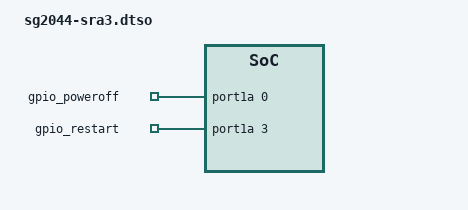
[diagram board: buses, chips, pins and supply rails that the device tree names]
/dts-v1/;
/plugin/;

&port1a {

	gpio_poweroff: gpio-poweroff {
		compatible = "gpio-poweroff";
		gpios = <&port1a 0 0>;
		active-delay-ms = <300>;
		inactive-delay-ms = <300>;
	};

	gpio_restart: gpio-restart {
		compatible = "gpio-restart";
		gpios = <&port1a 3 0>;
		active-delay-ms = <300>;
		inactive-delay-ms = <300>;
	};
};
